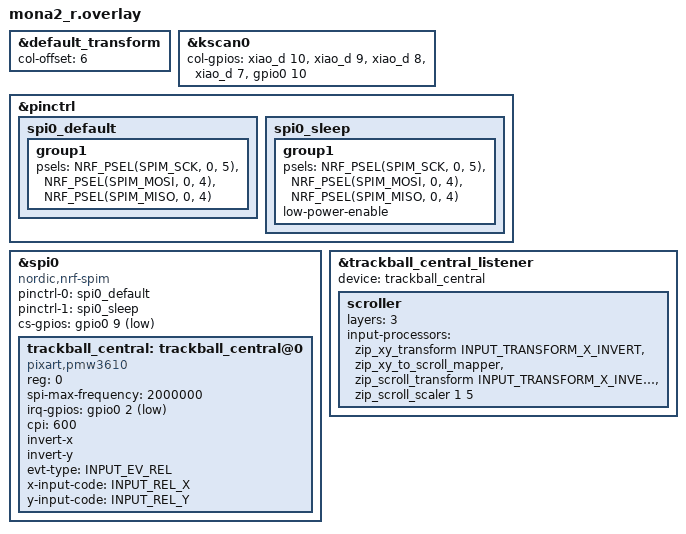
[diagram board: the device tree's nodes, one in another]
#include "mona2.dtsi"
#include <input/processors.dtsi>
#include <zephyr/dt-bindings/input/input-event-codes.h>


&default_transform {
    col-offset = <6>;
};

&kscan0 {
        col-gpios
            = <&xiao_d 10 GPIO_ACTIVE_HIGH>
            , <&xiao_d 9 GPIO_ACTIVE_HIGH> 
            , <&xiao_d 8 GPIO_ACTIVE_HIGH> 
            , <&xiao_d 7 GPIO_ACTIVE_HIGH> 
            , <&gpio0 10 GPIO_ACTIVE_HIGH>
            ;
};


&pinctrl {
    spi0_default: spi0_default {    //通常時(SPI通信中)のピン構成
        group1 {
            psels = <NRF_PSEL(SPIM_SCK, 0, 5)>, //P0.05を指定(SCLK)
                <NRF_PSEL(SPIM_MOSI, 0, 4)>,    //P0.04を指定(SDIOだからMOSI,MISO両方の役割を担う)
                <NRF_PSEL(SPIM_MISO, 0, 4)>;
        };
    };

    spi0_sleep: spi0_sleep {    //スリープ時のピン構成(省電力)
        group1 {
            psels = <NRF_PSEL(SPIM_SCK, 0, 5)>,
                <NRF_PSEL(SPIM_MOSI, 0, 4)>,
                <NRF_PSEL(SPIM_MISO, 0, 4)>;
            low-power-enable;
        };
    };
};


&spi0 {
    status = "okay";
    compatible = "nordic,nrf-spim"; //マイコンがnRFシリーズ
    pinctrl-0 = <&spi0_default>;
    pinctrl-1 = <&spi0_sleep>;
    pinctrl-names = "default", "sleep";
    cs-gpios = <&gpio0 9 GPIO_ACTIVE_LOW>;  //P0.09を指定(CS)

    trackball_central: trackball_central@0 {
        status = "okay";
        compatible = "pixart,pmw3610";  //トラボセンサ用のドライバとバインド
        reg = <0>;
        spi-max-frequency = <2000000>; // 上げると通信応答は速くなるが、配線品質が低いと不安定化する可能性あり
        irq-gpios = <&gpio0 2 (GPIO_ACTIVE_LOW | GPIO_PULL_UP)>; //P0.02を指定(MOTION)
        cpi = <600>; // 値を上げる: カーソルが速くなる / 値を下げる: カーソルが遅くなり微調整しやすい
        //swap-xy; // 有効化するとX/Y軸が入れ替わる（物理向きが90度ずれている場合の補正用）
        invert-x; // 有効化で左右反転（右へ転がして左へ動く場合に使う）。COROPIT版では有効化推奨
        invert-y; // 有効化で上下反転（上へ転がして下へ動く場合に使う）。COROPIT版では有効化推奨
        evt-type = <INPUT_EV_REL>;
        x-input-code = <INPUT_REL_X>;
        y-input-code = <INPUT_REL_Y>;
    };
};


// Overrides for the input listener node
&trackball_central_listener {
    status = "okay";
    device = <&trackball_central>;

    scroller {
        layers = <3>; // スクロール変換を有効化するレイヤー番号。例: <3 6> にすると layer 3 と 6 で有効
        input-processors = 
            // <&zip_xy_transform INPUT_TRANSFORM_XY_SWAP>,        // 有効化で「縦を回すと横スクロール」になる（X/Y入れ替え）
            <&zip_xy_transform INPUT_TRANSFORM_X_INVERT>,       // スクロール変換前のX反転（左右の向き調整）
            <&zip_xy_to_scroll_mapper>,                         // トラックボールのXY移動をスクロールイベントへ変換
            <&zip_scroll_transform INPUT_TRANSFORM_X_INVERT>,   // スクロール変換後のX反転（最終的な横スクロール向き調整）
            <&zip_scroll_scaler 1 5>;                           // 分子/分母でスクロール量を調整。1/5は控えめ、1/3で速く、1/8で遅くなる
    };

};
